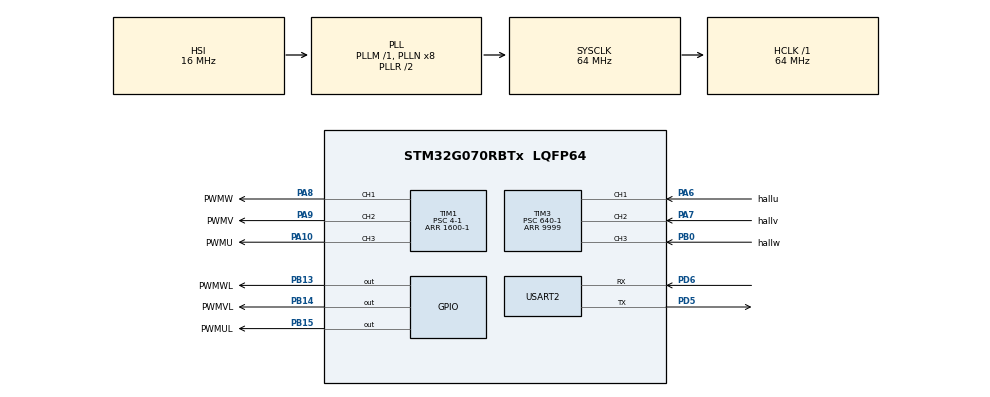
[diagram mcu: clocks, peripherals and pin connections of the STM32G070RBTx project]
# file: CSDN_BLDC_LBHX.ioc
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Mcu.Family=STM32G0
Mcu.Name=STM32G070RBTx
Mcu.Package=LQFP64
NVIC.TIM3_IRQn=true\:0\:0\:false\:false\:true\:true\:true\:true
PA10.GPIO_Label=PWMU
PA10.Signal=S_TIM1_CH3
PA13.Mode=Serial_Wire
PA13.Signal=SYS_SWDIO
PA14-BOOT0.Mode=Serial_Wire
PA14-BOOT0.Signal=SYS_SWCLK
PA6.GPIO_Label=hallu
PA6.Signal=S_TIM3_CH1
PA7.GPIO_Label=hallv
PA7.Signal=S_TIM3_CH2
PA8.GPIO_Label=PWMW
PA8.Signal=S_TIM1_CH1
PA9.GPIO_Label=PWMV
PA9.Signal=S_TIM1_CH2
PB0.GPIO_Label=hallw
PB0.Signal=S_TIM3_CH3
PB13.GPIO_Label=PWMWL
PB13.Signal=GPIO_Output
PB14.GPIO_Label=PWMVL
PB14.Signal=GPIO_Output
PB15.GPIO_Label=PWMUL
PB15.Signal=GPIO_Output
PD5.Mode=Asynchronous
PD5.Signal=USART2_TX
PD6.Mode=Asynchronous
PD6.Signal=USART2_RX
PF0-OSC_IN\ (PF0).Mode=HSE-External-Oscillator
PF0-OSC_IN\ (PF0).Signal=RCC_OSC_IN
PF1-OSC_OUT\ (PF1).Mode=HSE-External-Oscillator
PF1-OSC_OUT\ (PF1).Signal=RCC_OSC_OUT
ProjectManager.HeapSize=0x200
ProjectManager.StackSize=0x400
ProjectManager.TargetToolchain=MDK-ARM V5.27
RCC.ADCFreq_Value=64000000
RCC.AHBFreq_Value=64000000
RCC.CortexFreq_Value=64000000
RCC.EXTERNAL_CLOCK_VALUE=48000
RCC.HCLKFreq_Value=64000000
RCC.HSE_VALUE=8000000
RCC.HSI_VALUE=16000000
RCC.LSE_VALUE=32768
RCC.SYSCLKFreq_VALUE=64000000
RCC.SYSCLKSource=RCC_SYSCLKSOURCE_PLLCLK
RCC.VCOOutputFreq_Value=128000000
SH.S_TIM1_CH1.0=TIM1_CH1,PWM Generation1 CH1
SH.S_TIM1_CH2.0=TIM1_CH2,PWM Generation2 CH2
SH.S_TIM1_CH3.0=TIM1_CH3,PWM Generation3 CH3
SH.S_TIM3_CH1.0=TIM3_CH1,Xored_Inputs_Hall_Sensor_Interface
SH.S_TIM3_CH2.0=TIM3_CH2,Xored_Inputs_Hall_Sensor_Interface
SH.S_TIM3_CH3.0=TIM3_CH3,Xored_Inputs_Hall_Sensor_Interface
TIM1.Channel-PWM\ Generation1\ CH1=TIM_CHANNEL_1
TIM1.Channel-PWM\ Generation2\ CH2=TIM_CHANNEL_2
TIM1.Channel-PWM\ Generation3\ CH3=TIM_CHANNEL_3
TIM1.Period=1600-1
TIM1.Prescaler=4-1
TIM3.Period=9999
TIM3.Prescaler=640-1
USART2.VirtualMode-Asynchronous=VM_ASYNC
VP_SYS_VS_DBSignals.Mode=DisableDeadBatterySignals
VP_TIM1_VS_ClockSourceINT.Mode=Internal
board=custom

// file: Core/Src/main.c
/* USER CODE BEGIN Header */
/**
  ******************************************************************************
  * @file           : main.c
  * @brief          : Main program body
  ******************************************************************************
  * @attention
  *
  * Copyright (c) 2022 STMicroelectronics.
  * All rights reserved.
  *
  * This software is licensed under terms that can be found in the LICENSE file
  * in the root directory of this software component.
  * If no LICENSE file comes with this software, it is provided AS-IS.
  *
  ******************************************************************************
  */
/* USER CODE END Header */
#include "main.h"
#include "tim.h"
#include "usart.h"
#include "gpio.h"

/* USER CODE BEGIN Includes */
#include <stdio.h>
#include "hall.h"

/* USER CODE END Includes */

void SystemClock_Config(void);

int main(void)
{

  /* MCU Configuration--------------------------------------------------------*/

  /* Reset of all peripherals, Initializes the Flash interface and the Systick. */
  HAL_Init();

  /* Configure the system clock */
  SystemClock_Config();

  /* Initialize all configured peripherals */
  MX_GPIO_Init();
  MX_USART2_UART_Init();
  MX_TIM3_Init();
  MX_TIM1_Init();
  /* USER CODE BEGIN 2 */
//启动定时器霍尔模式及中断
	__HAL_TIM_ENABLE_IT(&htim3,TIM_IT_TRIGGER);  //触发：有某个信号触发。
	__HAL_TIM_ENABLE_IT(&htim3,TIM_IT_UPDATE);   //更新：有某个寄存器被更新。
	HAL_TIMEx_HallSensor_Start_IT(&htim3);
//启动PWM、初始化占空比
	HAL_TIM_PWM_Start(&htim1,TIM_CHANNEL_1);
	HAL_TIM_PWM_Start(&htim1,TIM_CHANNEL_2);
	HAL_TIM_PWM_Start(&htim1,TIM_CHANNEL_3);
	__HAL_TIM_SetCompare(&htim1,TIM_CHANNEL_3,0);	//U
	__HAL_TIM_SetCompare(&htim1,TIM_CHANNEL_2,0);	//V
	__HAL_TIM_SetCompare(&htim1,TIM_CHANNEL_1,0);	//W
//普通IO初始化，驱动3个下桥臂
	HAL_GPIO_WritePin(PWMUL_GPIO_Port,PWMUL_Pin,GPIO_PIN_RESET);//UL//GPIO_PIN_SET   GPIO_PIN_RESET
	HAL_GPIO_WritePin(PWMVL_GPIO_Port,PWMVL_Pin,GPIO_PIN_RESET);//VL
	HAL_GPIO_WritePin(PWMWL_GPIO_Port,PWMWL_Pin,GPIO_PIN_RESET);//WL

  /* USER CODE END 2 */

  /* Infinite loop */
  /* USER CODE BEGIN WHILE */
  while (1)
  {
//		printf("hello\r\n");
//		HAL_Delay(1000);
    /* USER CODE END WHILE */

  }
}

void SystemClock_Config(void)
{
  RCC_OscInitTypeDef RCC_OscInitStruct = {0};
  RCC_ClkInitTypeDef RCC_ClkInitStruct = {0};

  /** Configure the main internal regulator output voltage
  */
  HAL_PWREx_ControlVoltageScaling(PWR_REGULATOR_VOLTAGE_SCALE1);

  /** Initializes the RCC Oscillators according to the specified parameters
  * in the RCC_OscInitTypeDef structure.
  */
  RCC_OscInitStruct.OscillatorType = RCC_OSCILLATORTYPE_HSI;
  RCC_OscInitStruct.HSIState = RCC_HSI_ON;
  RCC_OscInitStruct.HSIDiv = RCC_HSI_DIV1;
  RCC_OscInitStruct.HSICalibrationValue = RCC_HSICALIBRATION_DEFAULT;
  RCC_OscInitStruct.PLL.PLLState = RCC_PLL_ON;
  RCC_OscInitStruct.PLL.PLLSource = RCC_PLLSOURCE_HSI;
  RCC_OscInitStruct.PLL.PLLM = RCC_PLLM_DIV1;
  RCC_OscInitStruct.PLL.PLLN = 8;
  RCC_OscInitStruct.PLL.PLLP = RCC_PLLP_DIV2;
  RCC_OscInitStruct.PLL.PLLR = RCC_PLLR_DIV2;
  if (HAL_RCC_OscConfig(&RCC_OscInitStruct) != HAL_OK)
  {
    Error_Handler();
  }

  /** Initializes the CPU, AHB and APB buses clocks
  */
  RCC_ClkInitStruct.ClockType = RCC_CLOCKTYPE_HCLK|RCC_CLOCKTYPE_SYSCLK
                              |RCC_CLOCKTYPE_PCLK1;
  RCC_ClkInitStruct.SYSCLKSource = RCC_SYSCLKSOURCE_PLLCLK;
  RCC_ClkInitStruct.AHBCLKDivider = RCC_SYSCLK_DIV1;
  RCC_ClkInitStruct.APB1CLKDivider = RCC_HCLK_DIV1;

  if (HAL_RCC_ClockConfig(&RCC_ClkInitStruct, FLASH_LATENCY_2) != HAL_OK)
  {
    Error_Handler();
  }
}

void Error_Handler(void)
{
  __disable_irq();
  while (1)
  {
  }
}
